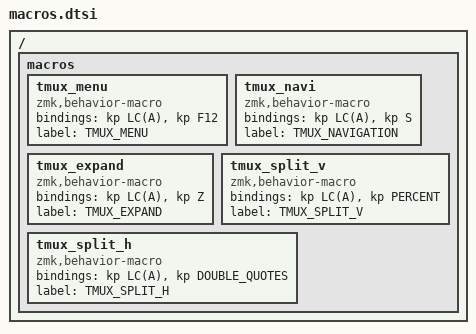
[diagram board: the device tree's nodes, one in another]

/ {
macros {
        tmux_menu: tmux_menu {
            compatible = "zmk,behavior-macro";
            #binding-cells = <0>;
            bindings = <&kp LC(A) &kp F12>;
            label = "TMUX_MENU";
        };

        tmux_navi: tmux_navi {
            compatible = "zmk,behavior-macro";
            #binding-cells = <0>;
            bindings = <&kp LC(A) &kp S>;
            label = "TMUX_NAVIGATION";
        };

        tmux_expand: tmux_expand {
            compatible = "zmk,behavior-macro";
            #binding-cells = <0>;
            bindings = <&kp LC(A) &kp Z>;
            label = "TMUX_EXPAND";
        };

        tmux_split_v: tmux_split_v {
            compatible = "zmk,behavior-macro";
            #binding-cells = <0>;
            bindings = <&kp LC(A) &kp PERCENT>;
            label = "TMUX_SPLIT_V";
        };

        tmux_split_h: tmux_split_h {
            compatible = "zmk,behavior-macro";
            #binding-cells = <0>;
            bindings = <&kp LC(A) &kp DOUBLE_QUOTES>;
            label = "TMUX_SPLIT_H";
        };
    };
};
